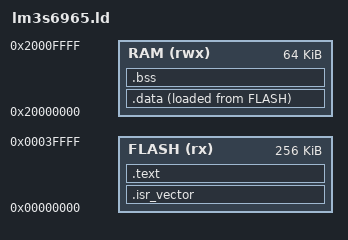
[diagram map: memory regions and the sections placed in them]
/* Entry Point */
ENTRY(Reset_Handler)

/* Memory layout for LM3S6965 */
MEMORY
{
    FLASH (rx) : ORIGIN = 0x00000000, LENGTH = 256K
    RAM (rwx)  : ORIGIN = 0x20000000, LENGTH = 64K
}

/* Define the top of the stack at the end of RAM */
_estack = ORIGIN(RAM) + LENGTH(RAM);

SECTIONS
{
    /* The vector table goes to the start of FLASH */
    .isr_vector :
    {
        . = ALIGN(4);
        KEEP(*(.isr_vector))
        . = ALIGN(4);
    } > FLASH

    /* The program code and other data goes into FLASH */
    .text :
    {
        . = ALIGN(4);
        *(.text)           /* .text sections (code) */
        *(.text*)          /* .text* sections (code) */
        *(.rodata)         /* .rodata sections (constants, strings, etc.) */
        *(.rodata*)        /* .rodata* sections (constants, strings, etc.) */
        . = ALIGN(4);
        _etext = .;        /* define a global symbol at end of code */
    } > FLASH

    /* Initialize data section used by the startup code to initialize data */
    _sidata = LOADADDR(.data);

    /* Initialized data sections goes into RAM, load LMA copy after code */
    .data :
    {
        . = ALIGN(4);
        _sdata = .;        /* create a global symbol at data start */
        *(.data)           /* .data sections */
        *(.data*)          /* .data* sections */
        . = ALIGN(4);
        _edata = .;        /* define a global symbol at data end */
    } > RAM AT> FLASH

    /* Uninitialized data section */
    .bss :
    {
        . = ALIGN(4);
        _sbss = .;         /* define a global symbol at bss start */
        __bss_start__ = _sbss;
        *(.bss)
        *(.bss*)
        *(COMMON)
        . = ALIGN(4);
        _ebss = .;         /* define a global symbol at bss end */
        __bss_end__ = _ebss;
        
        /* [FIX] Define 'end' symbol for _sbrk (required by newlib/semihosting) */
        end = .;
        __end__ = .;
    } > RAM
}
